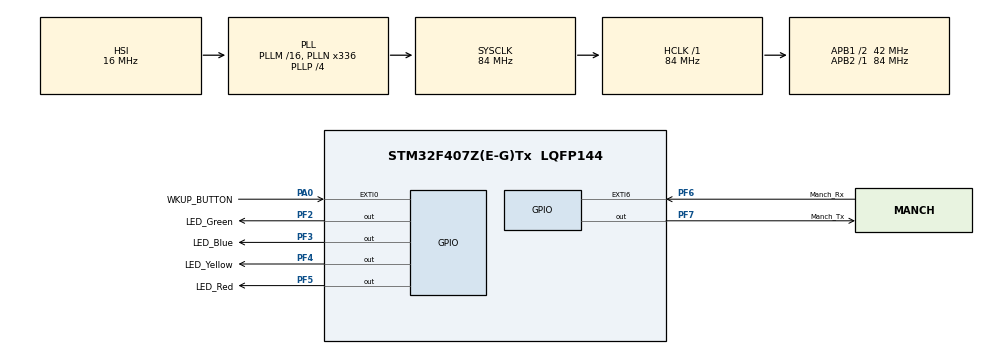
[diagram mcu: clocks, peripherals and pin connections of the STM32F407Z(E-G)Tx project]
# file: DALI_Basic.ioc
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Mcu.Family=STM32F4
Mcu.Name=STM32F407Z(E-G)Tx
Mcu.Package=LQFP144
NVIC.EXTI9_5_IRQn=true\:1\:0\:true\:false\:true\:true
NVIC.PriorityGroup=NVIC_PRIORITYGROUP_4
NVIC.TIM2_IRQn=true\:1\:0\:true\:false\:true\:true
PA0-WKUP.GPIO_Label=WKUP_BUTTON
PA0-WKUP.GPIO_PuPd=GPIO_PULLDOWN
PA0-WKUP.Signal=GPXTI0
PF2.GPIO_Label=LED_Green
PF2.GPIO_PuPd=GPIO_PULLDOWN
PF2.Signal=GPIO_Output
PF3.GPIO_Label=LED_Blue
PF3.GPIO_PuPd=GPIO_PULLDOWN
PF3.Signal=GPIO_Output
PF4.GPIO_Label=LED_Yellow
PF4.GPIO_PuPd=GPIO_PULLDOWN
PF4.Signal=GPIO_Output
PF5.GPIO_Label=LED_Red
PF5.GPIO_PuPd=GPIO_PULLDOWN
PF5.Signal=GPIO_Output
PF6.GPIO_Label=Manch_Rx
PF6.GPIO_PuPd=GPIO_PULLDOWN
PF6.Signal=GPXTI6
PF7.GPIO_Label=Manch_Tx
PF7.GPIO_PuPd=GPIO_PULLDOWN
PF7.Signal=GPIO_Output
ProjectManager.HeapSize=0x200
ProjectManager.StackSize=0x400
ProjectManager.TargetToolchain=Makefile
RCC.48MHZClocksFreq_Value=84000000
RCC.AHBFreq_Value=84000000
RCC.APB1CLKDivider=RCC_HCLK_DIV2
RCC.APB1Freq_Value=42000000
RCC.APB1TimFreq_Value=84000000
RCC.APB2Freq_Value=84000000
RCC.APB2TimFreq_Value=84000000
RCC.CortexFreq_Value=84000000
RCC.HCLKFreq_Value=84000000
RCC.HSE_VALUE=25000000
RCC.HSI_VALUE=16000000
RCC.LSE_VALUE=32768
RCC.PLLN=336
RCC.PLLP=RCC_PLLP_DIV4
RCC.SYSCLKFreq_VALUE=84000000
RCC.SYSCLKSource=RCC_SYSCLKSOURCE_PLLCLK
RCC.VCOOutputFreq_Value=336000000
TIM2.Period=103
TIM2.Prescaler=83
VP_TIM2_VS_ClockSourceINT.Mode=Internal
board=DALI_Basic

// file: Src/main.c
/**
  ******************************************************************************
  * File Name          : main.c
  * Description        : Main program body
  ******************************************************************************
  ** This notice applies to any and all portions of this file
  * that are not between comment pairs USER CODE BEGIN and
  * USER CODE END. Other portions of this file, whether
  * inserted by the user or by software development tools
  * are owned by their respective copyright owners.
  *
  * COPYRIGHT(c) 2017 STMicroelectronics
  *
  * Redistribution and use in source and binary forms, with or without modification,
  * are permitted provided that the following conditions are met:
  *   1. Redistributions of source code must retain the above copyright notice,
  *      this list of conditions and the following disclaimer.
  *   2. Redistributions in binary form must reproduce the above copyright notice,
  *      this list of conditions and the following disclaimer in the documentation
  *      and/or other materials provided with the distribution.
  *   3. Neither the name of STMicroelectronics nor the names of its contributors
  *      may be used to endorse or promote products derived from this software
  *      without specific prior written permission.
  *
  * THIS SOFTWARE IS PROVIDED BY THE COPYRIGHT HOLDERS AND CONTRIBUTORS "AS IS"
  * AND ANY EXPRESS OR IMPLIED WARRANTIES, INCLUDING, BUT NOT LIMITED TO, THE
  * IMPLIED WARRANTIES OF MERCHANTABILITY AND FITNESS FOR A PARTICULAR PURPOSE ARE
  * DISCLAIMED. IN NO EVENT SHALL THE COPYRIGHT HOLDER OR CONTRIBUTORS BE LIABLE
  * FOR ANY DIRECT, INDIRECT, INCIDENTAL, SPECIAL, EXEMPLARY, OR CONSEQUENTIAL
  * DAMAGES (INCLUDING, BUT NOT LIMITED TO, PROCUREMENT OF SUBSTITUTE GOODS OR
  * SERVICES; LOSS OF USE, DATA, OR PROFITS; OR BUSINESS INTERRUPTION) HOWEVER
  * CAUSED AND ON ANY THEORY OF LIABILITY, WHETHER IN CONTRACT, STRICT LIABILITY,
  * OR TORT (INCLUDING NEGLIGENCE OR OTHERWISE) ARISING IN ANY WAY OUT OF THE USE
  * OF THIS SOFTWARE, EVEN IF ADVISED OF THE POSSIBILITY OF SUCH DAMAGE.
  *
  ******************************************************************************
  */

#include "main.h"
#include "stm32f4xx_hal.h"

/* USER CODE BEGIN Includes */
#include "DALI_Master_ll.h"
#include "DALI_Master_defs.h"
#include "DALI_defs.h"
/* USER CODE END Includes */

TIM_HandleTypeDef htim2;

/* USER CODE BEGIN PV */
/* Private variables ---------------------------------------------------------*/

/* USER CODE END PV */

void SystemClock_Config(void);
static void MX_GPIO_Init(void);
static void MX_TIM2_Init(void);

/* USER CODE BEGIN PFP */
/* Private function prototypes -----------------------------------------------*/

/* USER CODE END PFP */

int main(void)
{

  /* MCU Configuration----------------------------------------------------------*/

  /* Reset of all peripherals, Initializes the Flash interface and the Systick. */
  HAL_Init();

  /* Configure the system clock */
  SystemClock_Config();

  /* Initialize all configured peripherals */
  MX_GPIO_Init();
  MX_TIM2_Init();

  /* USER CODE BEGIN 2 */
  /* Initialize DALI network - master device*/
  DALI_Master_Init();
  /* USER CODE END 2 */

  /* Infinite loop */
  while (1)
  {

  /* USER CODE BEGIN 3 */
    /* Here the code to display the response received from DALI_Slave should be there*/
    /* Sth like if the dali_state == BACKWARD_FRAME_RECEIVED, execute
  code to display the dali_master_array_receive_buffer through Serial
  Com on laptop or proper GUI display */

    /* get DALI status - master */
    /* Also this calls for the DALI_Master_Status() function in
    DALI_Master_ll.c, which continuously check for dali_status and
    executes appropriate code */
    dali_state = DALI_Master_Status();
  }
  /* USER CODE END 3 */

}

/** System Clock Configuration
*/
void SystemClock_Config(void)
{

  RCC_OscInitTypeDef RCC_OscInitStruct;
  RCC_ClkInitTypeDef RCC_ClkInitStruct;

    /**Configure the main internal regulator output voltage
    */
  __HAL_RCC_PWR_CLK_ENABLE();

  __HAL_PWR_VOLTAGESCALING_CONFIG(PWR_REGULATOR_VOLTAGE_SCALE1);

    /**Initializes the CPU, AHB and APB busses clocks
    */
  RCC_OscInitStruct.OscillatorType = RCC_OSCILLATORTYPE_HSI;
  RCC_OscInitStruct.HSIState = RCC_HSI_ON;
  RCC_OscInitStruct.HSICalibrationValue = 16;
  RCC_OscInitStruct.PLL.PLLState = RCC_PLL_ON;
  RCC_OscInitStruct.PLL.PLLSource = RCC_PLLSOURCE_HSI;
  RCC_OscInitStruct.PLL.PLLM = 16;
  RCC_OscInitStruct.PLL.PLLN = 336;
  RCC_OscInitStruct.PLL.PLLP = RCC_PLLP_DIV4;
  RCC_OscInitStruct.PLL.PLLQ = 4;
  if (HAL_RCC_OscConfig(&RCC_OscInitStruct) != HAL_OK)
  {
    _Error_Handler(__FILE__, __LINE__);
  }

    /**Initializes the CPU, AHB and APB busses clocks
    */
  RCC_ClkInitStruct.ClockType = RCC_CLOCKTYPE_HCLK|RCC_CLOCKTYPE_SYSCLK
                              |RCC_CLOCKTYPE_PCLK1|RCC_CLOCKTYPE_PCLK2;
  RCC_ClkInitStruct.SYSCLKSource = RCC_SYSCLKSOURCE_PLLCLK;
  RCC_ClkInitStruct.AHBCLKDivider = RCC_SYSCLK_DIV1;
  RCC_ClkInitStruct.APB1CLKDivider = RCC_HCLK_DIV2;
  RCC_ClkInitStruct.APB2CLKDivider = RCC_HCLK_DIV1;

  if (HAL_RCC_ClockConfig(&RCC_ClkInitStruct, FLASH_LATENCY_2) != HAL_OK)
  {
    _Error_Handler(__FILE__, __LINE__);
  }

    /**Configure the Systick interrupt time
    */
  HAL_SYSTICK_Config(HAL_RCC_GetHCLKFreq()/1000);

    /**Configure the Systick
    */
  HAL_SYSTICK_CLKSourceConfig(SYSTICK_CLKSOURCE_HCLK);

  /* SysTick_IRQn interrupt configuration */
  HAL_NVIC_SetPriority(SysTick_IRQn, 0, 0);
}

/* TIM2 init function */
static void MX_TIM2_Init(void)
{

  TIM_ClockConfigTypeDef sClockSourceConfig;
  TIM_MasterConfigTypeDef sMasterConfig;

  htim2.Instance = TIM2;
  htim2.Init.Prescaler = 83;
  htim2.Init.CounterMode = TIM_COUNTERMODE_UP;
  htim2.Init.Period = 103;
  htim2.Init.ClockDivision = TIM_CLOCKDIVISION_DIV1;
  if (HAL_TIM_Base_Init(&htim2) != HAL_OK)
  {
    _Error_Handler(__FILE__, __LINE__);
  }

  sClockSourceConfig.ClockSource = TIM_CLOCKSOURCE_INTERNAL;
  if (HAL_TIM_ConfigClockSource(&htim2, &sClockSourceConfig) != HAL_OK)
  {
    _Error_Handler(__FILE__, __LINE__);
  }

  sMasterConfig.MasterOutputTrigger = TIM_TRGO_RESET;
  sMasterConfig.MasterSlaveMode = TIM_MASTERSLAVEMODE_DISABLE;
  if (HAL_TIMEx_MasterConfigSynchronization(&htim2, &sMasterConfig) != HAL_OK)
  {
    _Error_Handler(__FILE__, __LINE__);
  }

}

/** Configure pins as
        * Analog
        * Input
        * Output
        * EVENT_OUT
        * EXTI
*/
static void MX_GPIO_Init(void)
{

  GPIO_InitTypeDef GPIO_InitStruct;

  /* GPIO Ports Clock Enable */
  __HAL_RCC_GPIOF_CLK_ENABLE();
  __HAL_RCC_GPIOA_CLK_ENABLE();

  /*Configure GPIO pin Output Level */
  HAL_GPIO_WritePin(GPIOF, LED_Green_Pin|LED_Blue_Pin|LED_Yellow_Pin|LED_Red_Pin
                          |Manch_Tx_Pin, GPIO_PIN_RESET);

  /*Configure GPIO pins : LED_Green_Pin LED_Blue_Pin LED_Yellow_Pin LED_Red_Pin
                           Manch_Tx_Pin */
  GPIO_InitStruct.Pin = LED_Green_Pin|LED_Blue_Pin|LED_Yellow_Pin|LED_Red_Pin
                          |Manch_Tx_Pin;
  GPIO_InitStruct.Mode = GPIO_MODE_OUTPUT_PP;
  GPIO_InitStruct.Pull = GPIO_PULLDOWN;
  GPIO_InitStruct.Speed = GPIO_SPEED_FREQ_LOW;
  HAL_GPIO_Init(GPIOF, &GPIO_InitStruct);

  /*Configure GPIO pin : Manch_Rx_Pin */
  GPIO_InitStruct.Pin = Manch_Rx_Pin;
  GPIO_InitStruct.Mode = GPIO_MODE_IT_RISING;
  GPIO_InitStruct.Pull = GPIO_PULLDOWN;
  HAL_GPIO_Init(Manch_Rx_GPIO_Port, &GPIO_InitStruct);

  /*Configure GPIO pin : WKUP_BUTTON_Pin */
  GPIO_InitStruct.Pin = WKUP_BUTTON_Pin;
  GPIO_InitStruct.Mode = GPIO_MODE_IT_RISING;
  GPIO_InitStruct.Pull = GPIO_PULLDOWN;
  HAL_GPIO_Init(WKUP_BUTTON_GPIO_Port, &GPIO_InitStruct);

  /* EXTI interrupt init*/
  HAL_NVIC_SetPriority(EXTI9_5_IRQn, 1, 0);
  HAL_NVIC_EnableIRQ(EXTI9_5_IRQn);

}

void _Error_Handler(char * file, int line)
{
  while(1)
  {
  }
}

/************************ (C) COPYRIGHT STMicroelectronics *****END OF FILE****/
